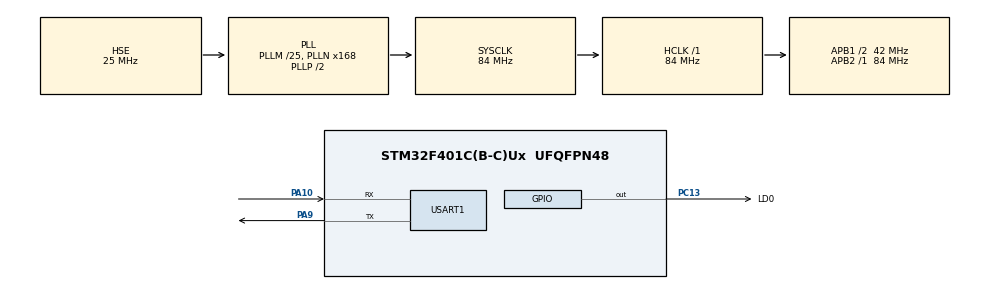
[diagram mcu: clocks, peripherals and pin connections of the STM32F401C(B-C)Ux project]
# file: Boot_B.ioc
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Dma.Request0=USART1_RX
Dma.USART1_RX.0.Direction=DMA_PERIPH_TO_MEMORY
Dma.USART1_RX.0.FIFOMode=DMA_FIFOMODE_DISABLE
Dma.USART1_RX.0.Instance=DMA2_Stream5
Dma.USART1_RX.0.MemDataAlignment=DMA_MDATAALIGN_BYTE
Dma.USART1_RX.0.MemInc=DMA_MINC_ENABLE
Dma.USART1_RX.0.Mode=DMA_NORMAL
Dma.USART1_RX.0.PeriphDataAlignment=DMA_PDATAALIGN_BYTE
Dma.USART1_RX.0.PeriphInc=DMA_PINC_DISABLE
Dma.USART1_RX.0.Priority=DMA_PRIORITY_MEDIUM
Mcu.Family=STM32F4
Mcu.Name=STM32F401C(B-C)Ux
Mcu.Package=UFQFPN48
NVIC.DMA2_Stream5_IRQn=true\:0\:0\:false\:false\:true\:false\:true\:true
NVIC.PriorityGroup=NVIC_PRIORITYGROUP_4
NVIC.TIM4_IRQn=true\:1\:0\:true\:false\:true\:true\:true\:true
NVIC.USART1_IRQn=true\:0\:0\:false\:false\:true\:true\:true\:true
PA10.Mode=Asynchronous
PA10.Signal=USART1_RX
PA13.Mode=Serial_Wire
PA13.Signal=SYS_JTMS-SWDIO
PA14.Mode=Serial_Wire
PA14.Signal=SYS_JTCK-SWCLK
PA9.Mode=Asynchronous
PA9.Signal=USART1_TX
PC13-ANTI_TAMP.GPIO_Label=LD0
PC13-ANTI_TAMP.Signal=GPIO_Output
PC14-OSC32_IN.Mode=LSE-External-Oscillator
PC14-OSC32_IN.Signal=RCC_OSC32_IN
PC15-OSC32_OUT.Mode=LSE-External-Oscillator
PC15-OSC32_OUT.Signal=RCC_OSC32_OUT
PH0\ -\ OSC_IN.Mode=HSE-External-Oscillator
PH0\ -\ OSC_IN.Signal=RCC_OSC_IN
PH1\ -\ OSC_OUT.Mode=HSE-External-Oscillator
PH1\ -\ OSC_OUT.Signal=RCC_OSC_OUT
ProjectManager.HeapSize=0x200
ProjectManager.StackSize=0x400
ProjectManager.TargetToolchain=MDK-ARM V5.32
RCC.48MHZClocksFreq_Value=42000000
RCC.AHBFreq_Value=84000000
RCC.APB1CLKDivider=RCC_HCLK_DIV2
RCC.APB1Freq_Value=42000000
RCC.APB1TimFreq_Value=84000000
RCC.APB2Freq_Value=84000000
RCC.APB2TimFreq_Value=84000000
RCC.CortexFreq_Value=84000000
RCC.HCLKFreq_Value=84000000
RCC.HSE_VALUE=25000000
RCC.HSI_VALUE=16000000
RCC.PLLM=25
RCC.PLLN=168
RCC.PLLSourceVirtual=RCC_PLLSOURCE_HSE
RCC.SYSCLKFreq_VALUE=84000000
RCC.SYSCLKSource=RCC_SYSCLKSOURCE_PLLCLK
RCC.VCOOutputFreq_Value=168000000
TIM4.Period=9999
TIM4.Prescaler=83
USART1.VirtualMode=VM_ASYNC
VP_TIM4_VS_ClockSourceINT.Mode=Internal
board=custom

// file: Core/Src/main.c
/* USER CODE BEGIN Header */
/**
 ******************************************************************************
 * @file           : main.c
 * @brief          : Main program body
 ******************************************************************************
 * @attention
 *
 * Copyright (c) 2026 STMicroelectronics.
 * All rights reserved.
 *
 * This software is licensed under terms that can be found in the LICENSE file
 * in the root directory of this software component.
 * If no LICENSE file comes with this software, it is provided AS-IS.
 *
 ******************************************************************************
 */
/* USER CODE END Header */
#include "dma.h"
#include "gpio.h"
#include "main.h"
#include "tim.h"
#include "usart.h"

/* USER CODE BEGIN Includes */
#include "BootLoader.h"
#include "BootLoader_common.h"
#include "ModbusRTU.h"
#include "XMODEM.h"
#include "fsm_bootloader.h"
#include "fsm_event.h"
#include "ulog.h"
#include "boot_decode.h"
/* USER CODE END Includes */

/* USER CODE BEGIN PV */
Modbus_CommContext mb_comm = {0};
volatile uint8_t rxdata;

uint16_t Modbus_holding_regs[MODBUS_REG_COUNT] = {0};
volatile uint16_t Modbus_read_regs[MODBUS_REG_COUNT] = {0};
volatile uint16_t Modbus_write_regs[MODBUS_REG_COUNT] = {0};

MODBUS_Device Modbus_dev0;
XMODEM_Device xmodem;

Fsm_Struct state_descriptor[] = {
    [STATE_MODBUS_RECV] = {.state = STATE_MODBUS_RECV,
                           .entry = ModbusRecv_Entry,
                           .do_action = ModbusRecv_Do,
                           .exit = ModbusRecv_Exit},
    [STATE_PROG_UPGRADE] = {.state = STATE_PROG_UPGRADE,
                            .entry = ProgUpgrade_Entry,
                            .do_action = ProgUpgrade_Do,
                            .exit = ProgUpgrade_Exit},
    [STATE_JUMP_APP] = {.state = STATE_JUMP_APP,
                        .entry = JumpApp_Entry,
                        .do_action = JumpApp_Do,
                        .exit = JumpApp_Exit}};

version_info_t version;

/* USER CODE END PV */

void SystemClock_Config(void);

/* USER CODE BEGIN 0 */
void LED_MODE(uint8_t state) {
  static uint32_t lastticks = 0;
  static uint32_t gapticks = 0;
  if (HAL_GetTick() - lastticks > gapticks) {
    lastticks = HAL_GetTick();
    HAL_GPIO_TogglePin(LD0_GPIO_Port, LD0_Pin);
  }

  switch (state) {
  case 0:
    gapticks = 50; // Set gap time for state 0
    break;
  case 1:
    gapticks = 100; // Set gap time for state 1
    break;
  default:
    gapticks = 500; // Set gap time for default state
    break;
  }
}

void my_console_logger(ulog_level_t lvl, const char *msg) {
  printf("[%lu][%s]: %s\n", HAL_GetTick(), ulog_level_name(lvl), msg);
}
/* USER CODE END 0 */

int main(void) {

  /* MCU Configuration--------------------------------------------------------*/

  /* Reset of all peripherals, Initializes the Flash interface and the Systick.
   */
  HAL_Init();

  /* Configure the system clock */
  SystemClock_Config();

  /* Initialize all configured peripherals */
  MX_GPIO_Init();
  MX_DMA_Init();
  MX_TIM4_Init();
  MX_USART1_UART_Init();
  /* USER CODE BEGIN 2 */
  HAL_UARTEx_ReceiveToIdle_IT(&huart1, mb_comm.rx_buffer,
                               MODBUS_RX_BUFFER_SIZE);
  MODBUS_Init(&Modbus_dev0, 19, Modbus_holding_regs, Modbus_read_regs,
              Modbus_write_regs, MODBUS_REG_COUNT);
  Fsm_Init();
  XMODEM_Init(&xmodem, &huart1, Bootloader_FlashWriteBuffer, 2000, 5);
  Bootloader_Init();
	boot_decode_init();
  ULOG_INIT();
  ULOG_SUBSCRIBE(my_console_logger, ULOG_DEBUG_LEVEL);
  HAL_TIM_Base_Start_IT(&htim4);
  ULOG_INFO("Boot version %d:%d:%d\r\n", BOOT_VER_MAJOR, BOOT_VER_MINOR,
            BOOT_VER_PATCH);
  Version_Read(&version);
  ULOG_INFO("APP version %d:%d:%d\n", version.app_ver_major,
            version.app_ver_minor, version.app_ver_patch);
  ULOG_INFO("App size is %d bytes\n", version.app_end_addr - APP_ADDRESS);

  /* USER CODE END 2 */

  /* Infinite loop */
  /* USER CODE BEGIN WHILE */
  while (1) {
    Fsm_Process();
  }

  /* USER CODE END WHILE */

}

void SystemClock_Config(void) {
  RCC_OscInitTypeDef RCC_OscInitStruct = {0};
  RCC_ClkInitTypeDef RCC_ClkInitStruct = {0};

  /** Configure the main internal regulator output voltage
   */
  __HAL_RCC_PWR_CLK_ENABLE();
  __HAL_PWR_VOLTAGESCALING_CONFIG(PWR_REGULATOR_VOLTAGE_SCALE2);

  /** Initializes the RCC Oscillators according to the specified parameters
   * in the RCC_OscInitTypeDef structure.
   */
  RCC_OscInitStruct.OscillatorType = RCC_OSCILLATORTYPE_HSE;
  RCC_OscInitStruct.HSEState = RCC_HSE_ON;
  RCC_OscInitStruct.PLL.PLLState = RCC_PLL_ON;
  RCC_OscInitStruct.PLL.PLLSource = RCC_PLLSOURCE_HSE;
  RCC_OscInitStruct.PLL.PLLM = 25;
  RCC_OscInitStruct.PLL.PLLN = 168;
  RCC_OscInitStruct.PLL.PLLP = RCC_PLLP_DIV2;
  RCC_OscInitStruct.PLL.PLLQ = 4;
  if (HAL_RCC_OscConfig(&RCC_OscInitStruct) != HAL_OK) {
    Error_Handler();
  }

  /** Initializes the CPU, AHB and APB buses clocks
   */
  RCC_ClkInitStruct.ClockType = RCC_CLOCKTYPE_HCLK | RCC_CLOCKTYPE_SYSCLK |
                                RCC_CLOCKTYPE_PCLK1 | RCC_CLOCKTYPE_PCLK2;
  RCC_ClkInitStruct.SYSCLKSource = RCC_SYSCLKSOURCE_PLLCLK;
  RCC_ClkInitStruct.AHBCLKDivider = RCC_SYSCLK_DIV1;
  RCC_ClkInitStruct.APB1CLKDivider = RCC_HCLK_DIV2;
  RCC_ClkInitStruct.APB2CLKDivider = RCC_HCLK_DIV1;

  if (HAL_RCC_ClockConfig(&RCC_ClkInitStruct, FLASH_LATENCY_2) != HAL_OK) {
    Error_Handler();
  }
}

/* USER CODE BEGIN 4 */
void HAL_UARTEx_RxEventCallback(UART_HandleTypeDef *huart, uint16_t Size) {
  if (huart->Instance == USART1) {
		if(Fsm_IsInState() == STATE_PROG_UPGRADE)
		{
			XMODEM_UART_RxEventCallback(&xmodem, Size);
		}else{
			mb_comm.rx_len = Size;
			HAL_UARTEx_ReceiveToIdle_IT(&huart1, mb_comm.rx_buffer,
                               MODBUS_RX_BUFFER_SIZE);
		}

  }
}

void HAL_UART_TxCpltCallback(UART_HandleTypeDef *huart) {

if (huart->Instance == USART1) {

}
}

void HAL_TIM_PeriodElapsedCallback(TIM_HandleTypeDef *htim) {
  if (htim->Instance == TIM4) {
    Fsm_Run();
    LED_MODE(Fsm_IsInState());
  }
}
/* USER CODE END 4 */

void Error_Handler(void) {
  __disable_irq();
  while (1) {
  }
}

#ifdef USE_FULL_ASSERT
/**
 * @brief  Reports the name of the source file and the source line number
 *         where the assert_param error has occurred.
 * @param  file: pointer to the source file name
 * @param  line: assert_param error line source number
 * @retval None
 */
void assert_failed(uint8_t *file, uint32_t line) {
  /* USER CODE BEGIN 6 */
  /* User can add his own implementation to report the file name and line
     number, ex: printf("Wrong parameters value: file %s on line %d\r\n", file,
     line) */
  /* USER CODE END 6 */
}
#endif /* USE_FULL_ASSERT */
